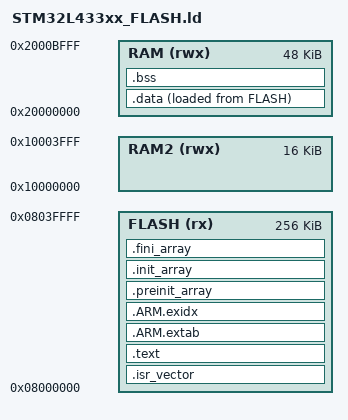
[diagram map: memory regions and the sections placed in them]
ENTRY(Reset_Handler)

MEMORY
{
    FLASH (rx)  : ORIGIN = 0x08000000, LENGTH = 256K
    RAM   (rwx) : ORIGIN = 0x20000000, LENGTH = 48K
    RAM2  (rwx) : ORIGIN = 0x10000000, LENGTH = 16K
}

_estack = ORIGIN(RAM) + LENGTH(RAM);

SECTIONS
{
    .isr_vector :
    {
        KEEP(*(.isr_vector))
    } > FLASH

    .text :
    {
        *(.text*)
        *(.rodata*)
        KEEP(*(.init))
        KEEP(*(.fini))
        . = ALIGN(4);
    } > FLASH

    .ARM.extab : { *(.ARM.extab*) } > FLASH
    .ARM.exidx : { *(.ARM.exidx*) } > FLASH

    .preinit_array :
    {
        PROVIDE_HIDDEN(__preinit_array_start = .);
        KEEP(*(.preinit_array*))
        PROVIDE_HIDDEN(__preinit_array_end = .);
    } > FLASH
    .init_array :
    {
        PROVIDE_HIDDEN(__init_array_start = .);
        KEEP(*(SORT(.init_array.*)))
        KEEP(*(.init_array*))
        PROVIDE_HIDDEN(__init_array_end = .);
    } > FLASH
    .fini_array :
    {
        PROVIDE_HIDDEN(__fini_array_start = .);
        KEEP(*(SORT(.fini_array.*)))
        KEEP(*(.fini_array*))
        PROVIDE_HIDDEN(__fini_array_end = .);
    } > FLASH

    .data :
    {
        . = ALIGN(4);
        _sdata = .;
        *(.data*)
        . = ALIGN(4);
        _edata = .;
    } > RAM AT > FLASH
    _sidata = LOADADDR(.data);

    .bss (NOLOAD) :
    {
        . = ALIGN(4);
        _sbss = .;
        *(.bss*)
        *(COMMON)
        . = ALIGN(4);
        _ebss = .;
    } > RAM
}

/* Reserve at least 1 KiB above the data for the descending stack. */
ASSERT(_ebss + 0x400 <= _estack, "RAM overflow: no room for stack")
